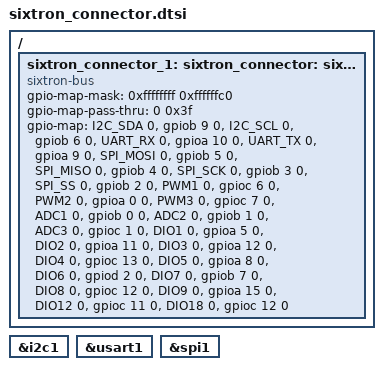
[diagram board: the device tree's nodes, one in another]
/*
 * Copyright (c) 2023 CATIE
 * SPDX-License-Identifier: Apache-2.0
 */

#include <zephyr/dt-bindings/gpio/sixtron-header.h>

/ {
    sixtron_connector_1: sixtron-connector-1 {
        compatible = "sixtron-bus";
        #gpio-cells = <2>;
        gpio-map-mask = <0xffffffff 0xffffffc0>;
        gpio-map-pass-thru = <0 0x3f>;
        gpio-map = <I2C_SDA 0 &gpiob 9 0>,
                   <I2C_SCL 0 &gpiob 6 0>,
                   <UART_RX 0 &gpioa 10 0>,
                   <UART_TX 0 &gpioa 9 0>,
                   <SPI_MOSI 0 &gpiob 5 0>,
                   <SPI_MISO 0 &gpiob 4 0>,
                   <SPI_SCK 0 &gpiob 3 0>,
                   <SPI_SS 0 &gpiob 2 0>,
                   <PWM1 0 &gpioc 6 0>,
                   <PWM2 0 &gpioa 0 0>,
                   <PWM3 0 &gpioc 7 0>,
                   <ADC1 0 &gpiob 0 0>,
                   <ADC2 0 &gpiob 1 0>,
                   <ADC3 0 &gpioc 1 0>,
                   <DIO1 0 &gpioa 5 0>,
                   <DIO2 0 &gpioa 11 0>,
                   <DIO3 0 &gpioa 12 0>,
                   <DIO4 0 &gpioc 13 0>,
                   <DIO5 0 &gpioa 8 0>,
                   <DIO6 0 &gpiod 2 0>,
                   <DIO7 0 &gpiob 7 0>,
                   <DIO8 0 &gpioc 12 0>,
                   <DIO9 0 &gpioa 15 0>,
                   <DIO12 0 &gpioc 11 0>,
                   <DIO18 0 &gpioc 12 0>;
    };
};

sixtron_connector_1_i2c: &i2c1 {};
sixtron_connector_1_uart: &usart1 {};
sixtron_connector_1_spi: &spi1 {};

sixtron_i2c: &sixtron_connector_1_i2c {};
sixtron_uart: &sixtron_connector_1_uart {};
sixtron_spi: &sixtron_connector_1_spi {};

sixtron_connector: &sixtron_connector_1 {};
